# ADSP-2183xW_HPC register map
Vendor: Analog Devices; Series: ADSP-2183xW_HPC; File version: 3.0.3.517
CPU: 
Registers are 32-bit, read-write, reset 0x0 unless marked. A register's access mark holds for its fields unless they carry their own. Offsets are from the block's base; [hi:lo] are bit positions; 'fields as' and 'values as' point back to an identical list.

## PKIC0 — Public Key Processor Interrupt Controller
Base 0x310D8000
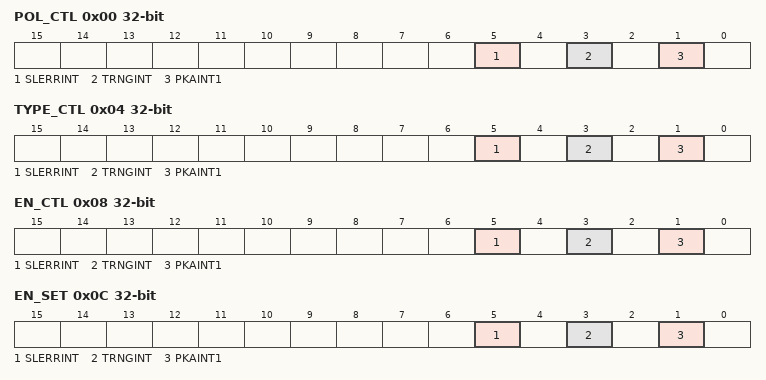
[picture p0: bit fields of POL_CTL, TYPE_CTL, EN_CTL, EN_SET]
0x00 POL_CTL — Polarity Control Register
  [5] SLERRINT — Completer Error IRQ
  [3] TRNGINT — TRNG IRQ
  [1] PKAINT1 — PKA Completion IRQ
0x04 TYPE_CTL — Type Control Register
  fields as POL_CTL
0x08 EN_CTL — Enable Control Register
  fields as POL_CTL
0x0C EN_SET — Enable Set Register
  fields as POL_CTL
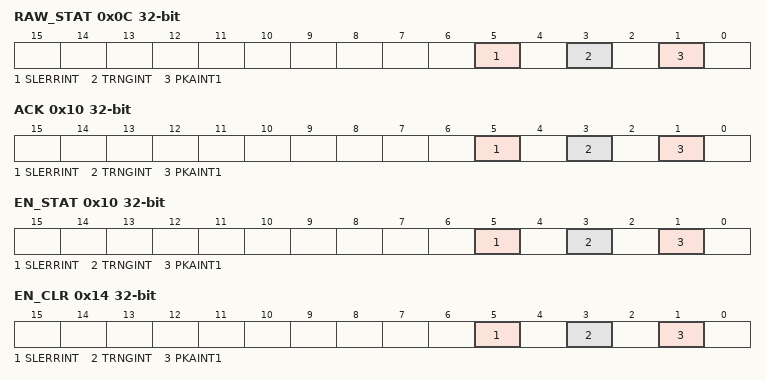
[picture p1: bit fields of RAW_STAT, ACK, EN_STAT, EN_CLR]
0x0C RAW_STAT (alternate view of EN_SET) — Raw Status Register
  [5] SLERRINT ro — ompleter Error IRQ
  [3] TRNGINT ro — TRNG IRQ
  [1] PKAINT1 ro — PKA Completion IRQ
0x10 ACK — Acknowledge Register
  [5] SLERRINT — Completer Error IRQ
  [3] TRNGINT — TRNG IRQ
  [1] PKAINT1 range 0x00000000..0x00000001 — PKA Completion IRQ
0x10 EN_STAT (alternate view of ACK) — Enabled Status Register
  [5] SLERRINT ro — Completer Error IRQ
  [3] TRNGINT ro — TRNG IRQ
  [1] PKAINT1 ro — PKA Completion IRQ
0x14 EN_CLR — Enable Clear Register
  fields as POL_CTL

## EMDMA1 — Extended Memory DMA
Base 0x310E0000
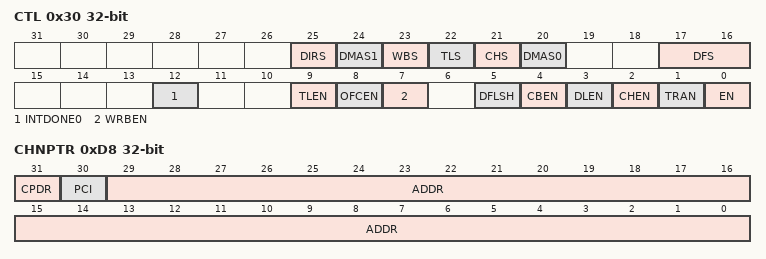
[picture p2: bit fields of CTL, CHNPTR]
0x30 CTL — External Memory DMA Control Register
  [25] DIRS ro — DMA Transfer Direction Status
  [24] DMAS1 ro — DMA External Interface Status
  [23] WBS ro — Write Back Status
  [22] TLS ro — TAP List Loading Status
  [21] CHS ro — DMA Chaining Status
  [20] DMAS0 ro — DMA Transfer Status
  [17:16] DFS ro — DMA FIFO Status
  [12] INTDONE0 — Internal DMA Completion Interrupt (Control)
  [9] TLEN — Tap List DMA Enable
  [8] OFCEN range 0x00000000..0x00000001 — On the Fly Control Loading Enable
  [7] WRBEN range 0x00000000..0x00000001 — Write Back Enable
  [5] DFLSH range 0x00000000..0x00000001 — Flush DMA FIFO
  [4] CBEN — Circular Buffering Enable
  [3] DLEN — Enable Delay Line DMA
  [2] CHEN — Enable Chaining
  [1] TRAN — DMA Direction
  [0] EN — DMA Enable
0xC0 INDX1 — External Index Register
  [29:0] VALUE range 0x00000000..0x3FFFFFFF — DMA External Address Index
0xC4 MOD1 — External Modifier Register
  [26:0] VALUE range 0x00000000..0x07FFFFFF — DMA External Address Modifier
0xC8 CNT1 — External Count Register
  [31:0] CNT1 ro — External Word Count
0xCC INDX0 — Internal Index Register
  [29:0] VALUE range 0x00000000..0x3FFFFFFF — DMA buffer Start Address
0xD0 MOD0 — Internal Modifier Register
  [15:0] VALUE range 0x00000000..0x0000FFFF — DMA Address Modifier
0xD4 CNT0 — Internal Count Register
  [31:0] VALUE range 0x00000000..0xFFFFFFFF — DMA Word Count
0xD8 CHNPTR — Chain Pointer Register
  [31] CPDR — CPDR DMA Direction for the next TCB
  [30] PCI — Program Controlled Interrupt
  [29:0] ADDR range 0x00000000..0x3FFFFFFF — Next Descriptor (Chain) Pointer Address
0xDC BASE — External Base Address Register
  [29:0] ADDR range 0x00000000..0x3FFFFFFF — External Delay Line Base Address
0xE0 TPTR — Tap List Pointer Register
  [29:0] VALUE range 0x00000000..0x3FFFFFFF — Delay Line Tap List Pointer
0xE4 BUFLEN — Circular Buffer Length Register
  [25:0] CLEN range 0x00000000..0x03FFFFFF — Delay Line Circular Buffer Length
0xEC TCNT — Delay Line Tap Count Register
  [31:0] VALUE range 0x00000000..0xFFFFFFFF — Delay Line Tap Count

## EMDMA0 — Extended Memory DMA
Base 0x310E0000
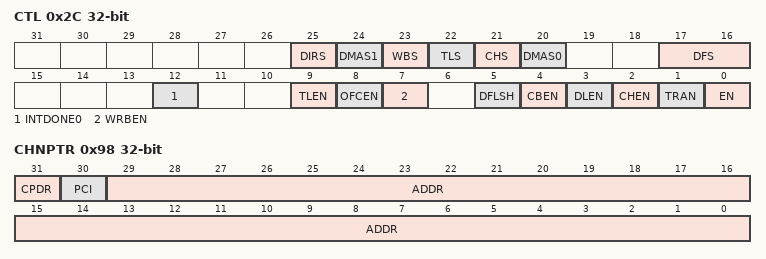
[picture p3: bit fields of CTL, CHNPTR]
0x2C CTL — External Memory DMA Control Register
  [25] DIRS ro — DMA Transfer Direction Status
  [24] DMAS1 ro — DMA External Interface Status
  [23] WBS ro — Write Back Status
  [22] TLS ro — TAP List Loading Status
  [21] CHS ro — DMA Chaining Status
  [20] DMAS0 ro — DMA Transfer Status
  [17:16] DFS ro — DMA FIFO Status
  [12] INTDONE0 — Internal DMA Completion Interrupt (Control)
  [9] TLEN — Tap List DMA Enable
  [8] OFCEN range 0x00000000..0x00000001 — On the Fly Control Loading Enable
  [7] WRBEN range 0x00000000..0x00000001 — Write Back Enable
  [5] DFLSH range 0x00000000..0x00000001 — Flush DMA FIFO
  [4] CBEN — Circular Buffering Enable
  [3] DLEN — Enable Delay Line DMA
  [2] CHEN — Enable Chaining
  [1] TRAN — DMA Direction
  [0] EN — DMA Enable
0x80 INDX1 — External Index Register
  [29:0] VALUE range 0x00000000..0x3FFFFFFF — DMA External Address Index
0x84 MOD1 — External Modifier Register
  [26:0] VALUE range 0x00000000..0x07FFFFFF — DMA External Address Modifier
0x88 CNT1 — External Count Register
  [31:0] CNT1 ro — External Word Count
0x8C INDX0 — Internal Index Register
  [29:0] VALUE range 0x00000000..0x3FFFFFFF — DMA buffer Start Address
0x90 MOD0 — Internal Modifier Register
  [15:0] VALUE range 0x00000000..0x0000FFFF — DMA Address Modifier
0x94 CNT0 — Internal Count Register
  [31:0] VALUE range 0x00000000..0xFFFFFFFF — DMA Word Count
0x98 CHNPTR — Chain Pointer Register
  [31] CPDR — CPDR DMA Direction for the next TCB
  [30] PCI — Program Controlled Interrupt
  [29:0] ADDR range 0x00000000..0x3FFFFFFF — Next Descriptor (Chain) Pointer Address
0x9C BASE — External Base Address Register
  [29:0] ADDR range 0x00000000..0x3FFFFFFF — External Delay Line Base Address
0xA0 TPTR — Tap List Pointer Register
  [29:0] VALUE range 0x00000000..0x3FFFFFFF — Delay Line Tap List Pointer
0xA4 BUFLEN — Circular Buffer Length Register
  [25:0] CLEN range 0x00000000..0x03FFFFFF — Delay Line Circular Buffer Length
0xAC TCNT — Delay Line Tap Count Register
  [31:0] VALUE range 0x00000000..0xFFFFFFFF — Delay Line Tap Count
